# lilium_network register map
Vendor: Nordic Semiconductor; Series: nrfXX; File version: 1
CPU: CM33 r0p4, little endian, MPU, no FPU, 3 interrupt priority bits, 30 interrupts
Registers are 32-bit, read-write, reset 0x0 unless marked. A register's access mark holds for its fields unless they carry their own. Offsets are from the block's base; [hi:lo] are bit positions; {n}, {i} and the like mark numbered series; 'fields as' and 'values as' point back to an identical list.

## ANACONF — Analog Trim and Configuration Registers
Base 0x41015000
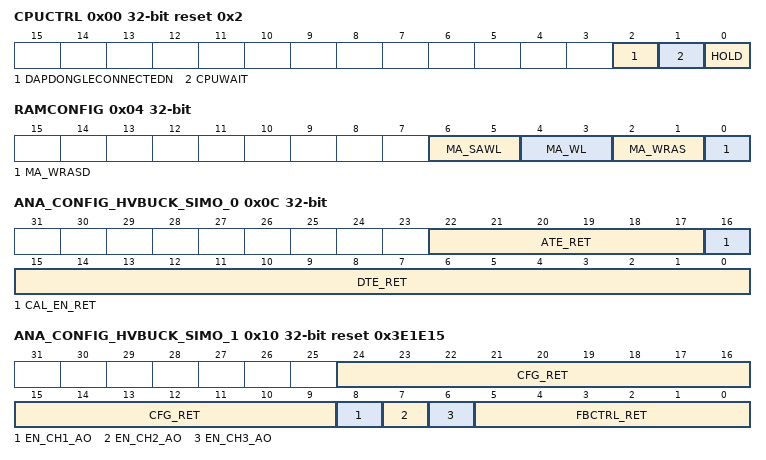
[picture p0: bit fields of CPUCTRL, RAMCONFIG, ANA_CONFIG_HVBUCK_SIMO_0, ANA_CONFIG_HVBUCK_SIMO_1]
0x00 CPUCTRL reset 0x2 — Control signals for CPU
  [2] DAPDONGLECONNECTEDN — Sets dapDongleConnected going to the CPU subsystem to 0. This prevents accessing with debugger when CPU is sleeping
  [1] CPUWAIT — Prevent the CPU From starting, still allows debugging to go through the CPU
  [0] HOLD — Block clock requests
0x04 RAMCONFIG — Trim for RAM
  [6:5] MA_SAWL — Margin Adjust: sense-amp timing and wordline pulse width
  [4:3] MA_WL — Margin Adjust: Wordline pulse width only
  [2:1] MA_WRAS — Margin Adjust: Write assist timings
  [0] MA_WRASD — Margin Adjust: Write assist function disabled
0x08 ANA_CONFIG_LATCH — Register for latching ANA_CONFIGn on digital island output.
  [0] LOCK — 0: Transparent, 1: Locked
0x0C ANA_CONFIG_HVBUCK_SIMO_0 — Control signals for additional analog modules (HVBUCK_SIMO_0)
  [22:17] ATE_RET, [16] CAL_EN_RET, [15:0] DTE_RET
0x10 ANA_CONFIG_HVBUCK_SIMO_1 reset 0x3E1E15 — Control signals for additional analog modules (HVBUCK_SIMO_1)
  [24:9] CFG_RET, [8] EN_CH1_AO, [7] EN_CH2_AO, [6] EN_CH3_AO, [5:0] FBCTRL_RET
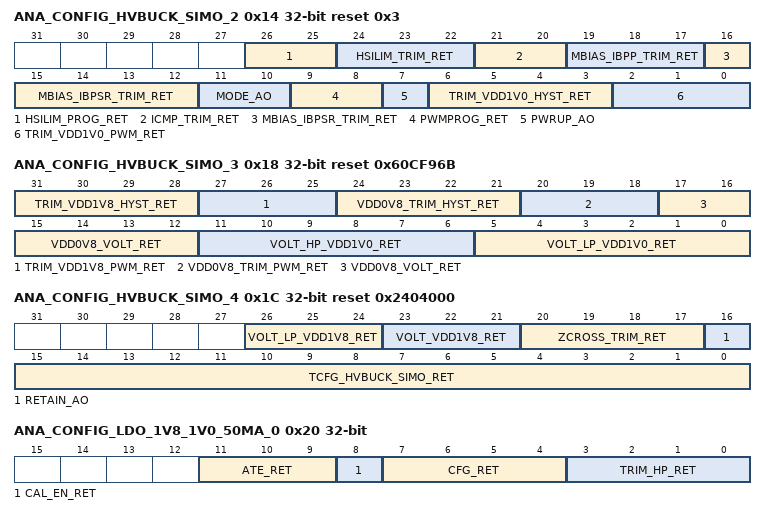
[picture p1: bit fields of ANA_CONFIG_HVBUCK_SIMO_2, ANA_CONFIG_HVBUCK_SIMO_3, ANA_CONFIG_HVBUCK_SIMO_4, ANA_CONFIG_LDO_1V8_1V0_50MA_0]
0x14 ANA_CONFIG_HVBUCK_SIMO_2 reset 0x3 — Control signals for additional analog modules (HVBUCK_SIMO_2)
  [26:25] HSILIM_PROG_RET, [24:22] HSILIM_TRIM_RET, [21:20] ICMP_TRIM_RET, [19:17] MBIAS_IBPP_TRIM_RET, [16:12] MBIAS_IBPSR_TRIM_RET, [11:10] MODE_AO, [9:8] PWMPROG_RET, [7] PWRUP_AO, [6:3] TRIM_VDD1V0_HYST_RET, [2:0] TRIM_VDD1V0_PWM_RET
0x18 ANA_CONFIG_HVBUCK_SIMO_3 reset 0x60CF96B — Control signals for additional analog modules (HVBUCK_SIMO_3)
  [31:28] TRIM_VDD1V8_HYST_RET, [27:25] TRIM_VDD1V8_PWM_RET, [24:21] VDD0V8_TRIM_HYST_RET, [20:18] VDD0V8_TRIM_PWM_RET, [17:12] VDD0V8_VOLT_RET, [11:6] VOLT_HP_VDD1V0_RET, [5:0] VOLT_LP_VDD1V0_RET
0x1C ANA_CONFIG_HVBUCK_SIMO_4 reset 0x2404000 — Control signals for additional analog modules (HVBUCK_SIMO_4)
  [26:24] VOLT_LP_VDD1V8_RET, [23:21] VOLT_VDD1V8_RET, [20:17] ZCROSS_TRIM_RET, [16] RETAIN_AO, [15:0] TCFG_HVBUCK_SIMO_RET
0x20 ANA_CONFIG_LDO_1V8_1V0_50MA_0 — Control signals for additional analog modules (LDO_1V8_1V0_50MA_0)
  [11:9] ATE_RET, [8] CAL_EN_RET, [7:4] CFG_RET, [3:0] TRIM_HP_RET
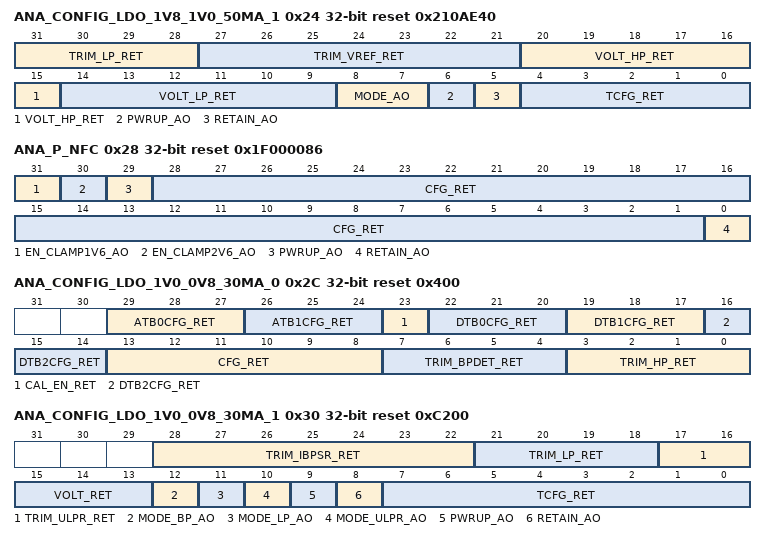
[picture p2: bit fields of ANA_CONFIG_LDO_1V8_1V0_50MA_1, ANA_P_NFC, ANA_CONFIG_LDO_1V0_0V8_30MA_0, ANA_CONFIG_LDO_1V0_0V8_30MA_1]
0x24 ANA_CONFIG_LDO_1V8_1V0_50MA_1 reset 0x210AE40 — Control signals for additional analog modules (LDO_1V8_1V0_50MA_1)
  [31:28] TRIM_LP_RET, [27:21] TRIM_VREF_RET, [20:15] VOLT_HP_RET, [14:9] VOLT_LP_RET, [8:7] MODE_AO, [6] PWRUP_AO, [5] RETAIN_AO, [4:0] TCFG_RET
0x28 ANA_P_NFC reset 0x1F000086 — Control signals for additional analog modules (P_NFC)
  [31] EN_CLAMP1V6_AO, [30] EN_CLAMP2V6_AO, [29] PWRUP_AO, [28:1] CFG_RET, [0] RETAIN_AO
0x2C ANA_CONFIG_LDO_1V0_0V8_30MA_0 reset 0x400 — Control signals for additional analog modules (LDO_1V0_0V8_30MA_0)
  [29:27] ATB0CFG_RET, [26:24] ATB1CFG_RET, [23] CAL_EN_RET, [22:20] DTB0CFG_RET, [19:17] DTB1CFG_RET, [16:14] DTB2CFG_RET, [13:8] CFG_RET, [7:4] TRIM_BPDET_RET, [3:0] TRIM_HP_RET
0x30 ANA_CONFIG_LDO_1V0_0V8_30MA_1 reset 0xC200 — Control signals for additional analog modules (LDO_1V0_0V8_30MA_1)
  [28:22] TRIM_IBPSR_RET, [21:18] TRIM_LP_RET, [17:16] TRIM_ULPR_RET, [15:13] VOLT_RET, [12] MODE_BP_AO, [11] MODE_LP_AO, [10] MODE_ULPR_AO, [9] PWRUP_AO, [8] RETAIN_AO, [7:0] TCFG_RET
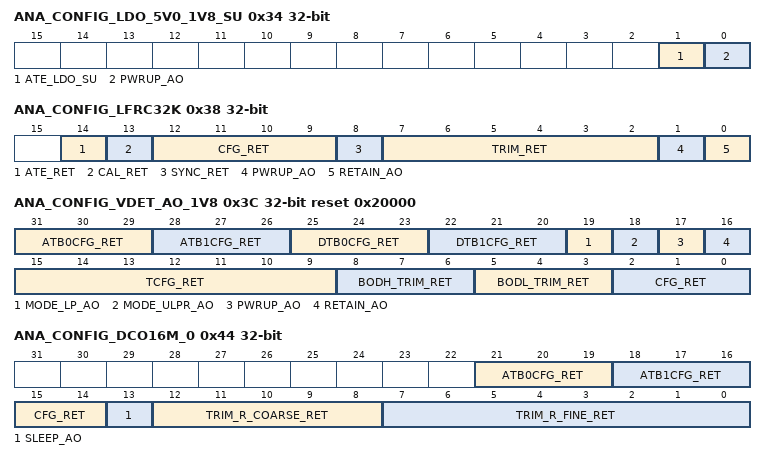
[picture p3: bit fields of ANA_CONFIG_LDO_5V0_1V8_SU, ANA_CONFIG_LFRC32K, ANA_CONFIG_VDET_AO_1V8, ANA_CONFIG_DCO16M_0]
0x34 ANA_CONFIG_LDO_5V0_1V8_SU — Control signals for additional analog modules (LDO_5V0_1V8_SU)
  [1] ATE_LDO_SU, [0] PWRUP_AO
0x38 ANA_CONFIG_LFRC32K — Control signals for additional analog modules (LFRC32K)
  [14] ATE_RET, [13] CAL_RET, [12:9] CFG_RET, [8] SYNC_RET, [7:2] TRIM_RET, [1] PWRUP_AO, [0] RETAIN_AO
0x3C ANA_CONFIG_VDET_AO_1V8 reset 0x20000 — Control signals for additional analog modules (VDET_AO_1V8)
  [31:29] ATB0CFG_RET, [28:26] ATB1CFG_RET, [25:23] DTB0CFG_RET, [22:20] DTB1CFG_RET, [19] MODE_LP_AO, [18] MODE_ULPR_AO, [17] PWRUP_AO, [16] RETAIN_AO, [15:9] TCFG_RET, [8:6] BODH_TRIM_RET, [5:3] BODL_TRIM_RET, [2:0] CFG_RET
0x40 ANA_CONFIG_VDET_ARSTCTRL — Control signals for additional analog modules (VDET_ARSTCTRL)
  [0] TRIM_READY_AO
0x44 ANA_CONFIG_DCO16M_0 — Control signals for additional analog modules (DCO16M_0)
  [21:19] ATB0CFG_RET, [18:16] ATB1CFG_RET, [15:14] CFG_RET, [13] SLEEP_AO, [12:8] TRIM_R_COARSE_RET, [7:0] TRIM_R_FINE_RET
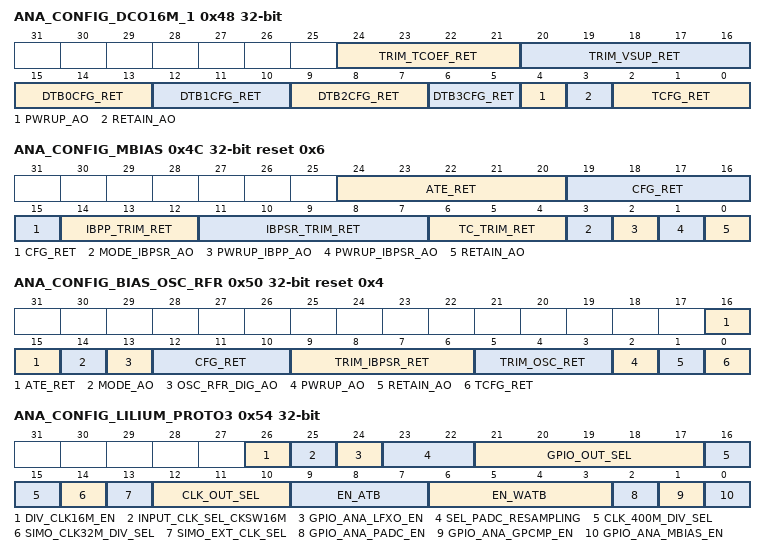
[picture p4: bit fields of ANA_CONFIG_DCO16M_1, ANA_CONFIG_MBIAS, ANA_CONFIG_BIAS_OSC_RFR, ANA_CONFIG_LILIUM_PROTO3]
0x48 ANA_CONFIG_DCO16M_1 — Control signals for additional analog modules (DCO16M_1)
  [24:21] TRIM_TCOEF_RET, [20:16] TRIM_VSUP_RET, [15:13] DTB0CFG_RET, [12:10] DTB1CFG_RET, [9:7] DTB2CFG_RET, [6:5] DTB3CFG_RET, [4] PWRUP_AO, [3] RETAIN_AO, [2:0] TCFG_RET
0x4C ANA_CONFIG_MBIAS reset 0x6 — Control signals for additional analog modules (MBIAS)
  [24:20] ATE_RET, [19:15] CFG_RET, [14:12] IBPP_TRIM_RET, [11:7] IBPSR_TRIM_RET, [6:4] TC_TRIM_RET, [3] MODE_IBPSR_AO, [2] PWRUP_IBPP_AO, [1] PWRUP_IBPSR_AO, [0] RETAIN_AO
0x50 ANA_CONFIG_BIAS_OSC_RFR reset 0x4 — Control signals for additional analog modules (BIAS_OSC_RFR)
  [16:15] ATE_RET, [14] MODE_AO, [13] OSC_RFR_DIG_AO, [12:10] CFG_RET, [9:6] TRIM_IBPSR_RET, [5:3] TRIM_OSC_RET, [2] PWRUP_AO, [1] RETAIN_AO, [0] TCFG_RET
0x54 ANA_CONFIG_LILIUM_PROTO3 — Control signals for additional analog modules (LILIUM_PROTO3)
  [26] DIV_CLK16M_EN, [25] INPUT_CLK_SEL_CKSW16M, [24] GPIO_ANA_LFXO_EN, [23:22] SEL_PADC_RESAMPLING, [21:17] GPIO_OUT_SEL, [16:15] CLK_400M_DIV_SEL, [14] SIMO_CLK32M_DIV_SEL, [13] SIMO_EXT_CLK_SEL, [12:10] CLK_OUT_SEL, [9:7] EN_ATB, [6:3] EN_WATB, [2] GPIO_ANA_PADC_EN, [1] GPIO_ANA_GPCMP_EN, [0] GPIO_ANA_MBIAS_EN
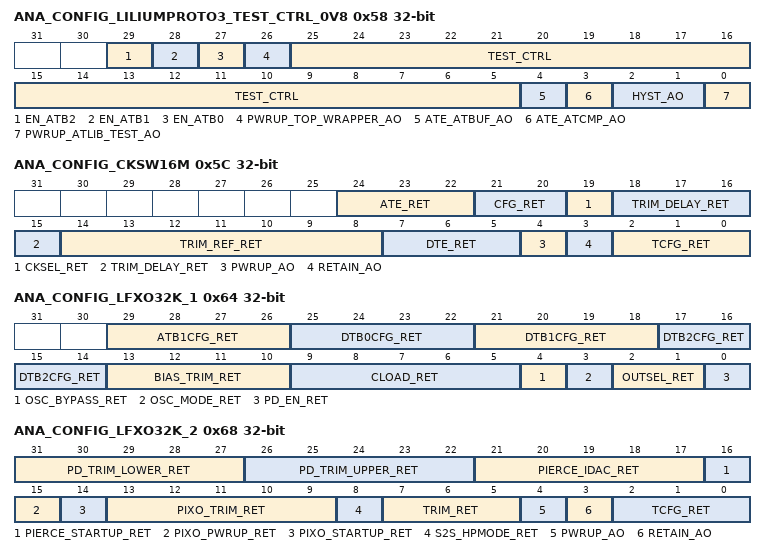
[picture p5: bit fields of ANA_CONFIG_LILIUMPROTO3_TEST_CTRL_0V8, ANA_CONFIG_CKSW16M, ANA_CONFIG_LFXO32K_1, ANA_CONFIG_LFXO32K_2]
0x58 ANA_CONFIG_LILIUMPROTO3_TEST_CTRL_0V8 — Control signals for additional analog modules (LILIUMPROTO3_TEST_CTRL_0V8)
  [29] EN_ATB2
  [28] EN_ATB1
  [27] EN_ATB0
  [26] PWRUP_TOP_WRAPPER_AO
  [25:5] TEST_CTRL — See anaip-gf22n_121
  [4] ATE_ATBUF_AO
  [3] ATE_ATCMP_AO
  [2:1] HYST_AO
  [0] PWRUP_ATLIB_TEST_AO
0x5C ANA_CONFIG_CKSW16M — Control signals for additional analog modules (CKSW16M)
  [24:22] ATE_RET, [21:20] CFG_RET, [19] CKSEL_RET, [18:15] TRIM_DELAY_RET, [14:8] TRIM_REF_RET, [7:5] DTE_RET, [4] PWRUP_AO, [3] RETAIN_AO, [2:0] TCFG_RET
0x60 ANA_CONFIG_LFXO32K_0 — Control signals for additional analog modules (LFXO32K_0)
  [3:0] ATB0CFG_RET
0x64 ANA_CONFIG_LFXO32K_1 — Control signals for additional analog modules (LFXO32K_1)
  [29:26] ATB1CFG_RET, [25:22] DTB0CFG_RET, [21:18] DTB1CFG_RET, [17:14] DTB2CFG_RET, [13:10] BIAS_TRIM_RET, [9:5] CLOAD_RET, [4] OSC_BYPASS_RET, [3] OSC_MODE_RET, [2:1] OUTSEL_RET, [0] PD_EN_RET
0x68 ANA_CONFIG_LFXO32K_2 — Control signals for additional analog modules (LFXO32K_2)
  [31:27] PD_TRIM_LOWER_RET, [26:22] PD_TRIM_UPPER_RET, [21:17] PIERCE_IDAC_RET, [16] PIERCE_STARTUP_RET, [15] PIXO_PWRUP_RET, [14] PIXO_STARTUP_RET, [13:9] PIXO_TRIM_RET, [8] S2S_HPMODE_RET, [7:5] TRIM_RET, [4] PWRUP_AO, [3] RETAIN_AO, [2:0] TCFG_RET
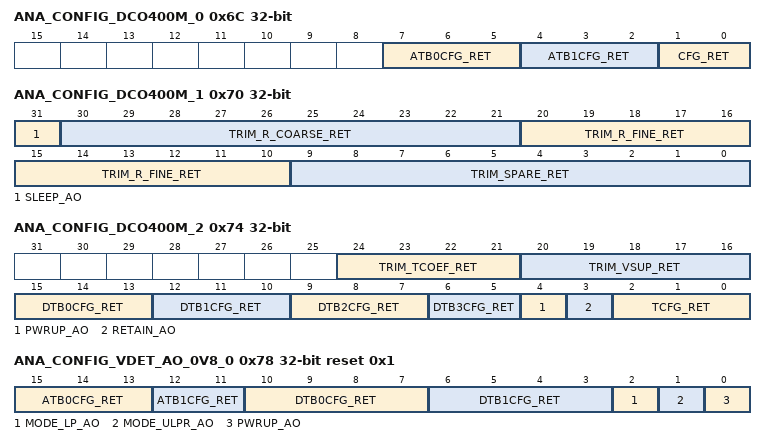
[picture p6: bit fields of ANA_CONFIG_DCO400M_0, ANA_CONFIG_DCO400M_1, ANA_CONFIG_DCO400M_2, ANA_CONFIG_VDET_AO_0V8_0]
0x6C ANA_CONFIG_DCO400M_0 — Control signals for additional analog modules (DCO400M_0)
  [7:5] ATB0CFG_RET, [4:2] ATB1CFG_RET, [1:0] CFG_RET
0x70 ANA_CONFIG_DCO400M_1 — Control signals for additional analog modules (DCO400M_1)
  [31] SLEEP_AO, [30:21] TRIM_R_COARSE_RET, [20:10] TRIM_R_FINE_RET, [9:0] TRIM_SPARE_RET
0x74 ANA_CONFIG_DCO400M_2 — Control signals for additional analog modules (DCO400M_2)
  fields as ANA_CONFIG_DCO16M_1
0x78 ANA_CONFIG_VDET_AO_0V8_0 reset 0x1 — Control signals for additional analog modules (VDET_AO_0V8_0)
  [15:13] ATB0CFG_RET, [12:11] ATB1CFG_RET, [10:7] DTB0CFG_RET, [6:3] DTB1CFG_RET, [2] MODE_LP_AO, [1] MODE_ULPR_AO, [0] PWRUP_AO
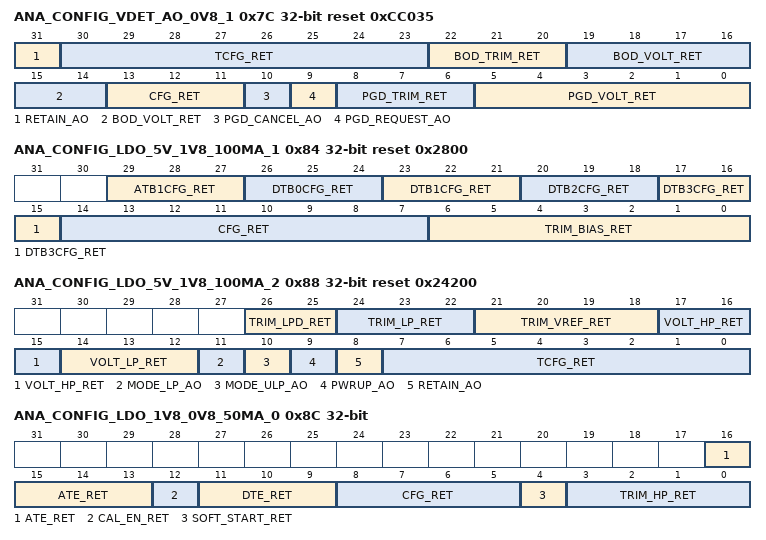
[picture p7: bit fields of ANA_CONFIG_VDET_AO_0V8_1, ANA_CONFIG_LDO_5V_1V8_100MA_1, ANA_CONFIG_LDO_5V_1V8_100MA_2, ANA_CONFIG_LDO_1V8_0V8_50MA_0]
0x7C ANA_CONFIG_VDET_AO_0V8_1 reset 0xCC035 — Control signals for additional analog modules (VDET_AO_0V8_1)
  [31] RETAIN_AO, [30:23] TCFG_RET, [22:20] BOD_TRIM_RET, [19:14] BOD_VOLT_RET, [13:11] CFG_RET, [10] PGD_CANCEL_AO, [9] PGD_REQUEST_AO, [8:6] PGD_TRIM_RET, [5:0] PGD_VOLT_RET
0x80 ANA_CONFIG_LDO_5V_1V8_100MA_0 — Control signals for additional analog modules (LDO_5V_1V8_100MA_0)
  [2:0] ATB0CFG_RET
0x84 ANA_CONFIG_LDO_5V_1V8_100MA_1 reset 0x2800 — Control signals for additional analog modules (LDO_5V_1V8_100MA_1)
  [29:27] ATB1CFG_RET, [26-3n:24-3n] DTB{n}CFG_RET (n=0..3), [14:7] CFG_RET, [6:0] TRIM_BIAS_RET
0x88 ANA_CONFIG_LDO_5V_1V8_100MA_2 reset 0x24200 — Control signals for additional analog modules (LDO_5V_1V8_100MA_2)
  [26:25] TRIM_LPD_RET, [24:22] TRIM_LP_RET, [21:18] TRIM_VREF_RET, [17:15] VOLT_HP_RET, [14:12] VOLT_LP_RET, [11] MODE_LP_AO, [10] MODE_ULP_AO, [9] PWRUP_AO, [8] RETAIN_AO, [7:0] TCFG_RET
0x8C ANA_CONFIG_LDO_1V8_0V8_50MA_0 — Control signals for additional analog modules (LDO_1V8_0V8_50MA_0)
  [16:13] ATE_RET, [12] CAL_EN_RET, [11:9] DTE_RET, [8:5] CFG_RET, [4] SOFT_START_RET, [3:0] TRIM_HP_RET
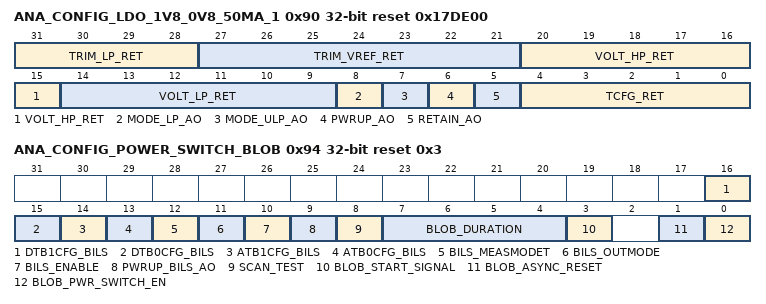
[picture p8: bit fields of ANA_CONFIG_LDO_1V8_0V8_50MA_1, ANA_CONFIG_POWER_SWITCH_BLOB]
0x90 ANA_CONFIG_LDO_1V8_0V8_50MA_1 reset 0x17DE00 — Control signals for additional analog modules (LDO_1V8_0V8_50MA_1)
  [31:28] TRIM_LP_RET, [27:21] TRIM_VREF_RET, [20:15] VOLT_HP_RET, [14:9] VOLT_LP_RET, [8] MODE_LP_AO, [7] MODE_ULP_AO, [6] PWRUP_AO, [5] RETAIN_AO, [4:0] TCFG_RET
0x94 ANA_CONFIG_POWER_SWITCH_BLOB reset 0x3 — Control signals for the PowerSwitchBlob and BILS module. For details on control of BILS refer to analog design description anaip_1017.
  [16] DTB1CFG_BILS, [15] DTB0CFG_BILS, [14] ATB1CFG_BILS, [13] ATB0CFG_BILS, [12] BILS_MEASMODET, [11] BILS_OUTMODE, [10] BILS_ENABLE, [9] PWRUP_BILS_AO, [8] SCAN_TEST, [7:4] BLOB_DURATION, [3] BLOB_START_SIGNAL, [1] BLOB_ASYNC_RESET, [0] BLOB_PWR_SWITCH_EN
{0xC+4i} ANA_CONFIG{i} (i=35..39) — Control signals for additional analog modules ({i})
  [31:0] OUT — Outputs from digital
0xAC BLOB_STATUS ro — Status signal from the PowerSwitchBlob
  [0] CHECK_OK — Checksum OK
